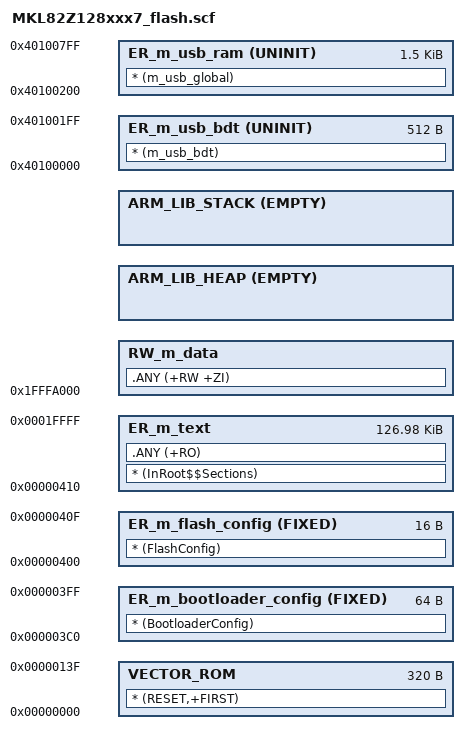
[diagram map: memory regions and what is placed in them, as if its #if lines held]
#! armcc -E
/*
** ###################################################################
**     Processors:          MKL82Z128VLH7
**                          MKL82Z128VLK7
**                          MKL82Z128VLL7
**                          MKL82Z128VMC7
**                          MKL82Z128VMP7
**
**     Compiler:            Keil ARM C/C++ Compiler
**     Reference manual:    KL82P121M72SF0RM, Rev.2 November 2015
**     Version:             rev. 1.5, 2015-09-24
**     Build:               b180801
**
**     Abstract:
**         Linker file for the Keil ARM C/C++ Compiler
**
**     Copyright 2016 Freescale Semiconductor, Inc.
**     Copyright 2016-2018 NXP
**
**     SPDX-License-Identifier: BSD-3-Clause
**
**     http:                 www.nxp.com
**     mail:                 support@nxp.com
**
** ###################################################################
*/

#define m_interrupts_start             0x00000000
#define m_interrupts_size              0x00000140

#define m_bootloader_config_start      0x000003C0
#define m_bootloader_config_size       0x00000040

#define m_flash_config_start           0x00000400
#define m_flash_config_size            0x00000010

#define m_text_start                   0x00000410
#define m_text_size                    0x0001FBF0

#define m_data_start                   0x1FFFA000
#define m_data_size                    0x00018000

#define m_usb_sram_start               0x40100000
#define m_usb_sram_size                0x00000800

/* USB BDT size */
#define usb_bdt_size                   0x200
/* Sizes */
#if (defined(__stack_size__))
  #define Stack_Size                   __stack_size__
#else
  #define Stack_Size                   0x2000
#endif

#if (defined(__heap_size__))
  #define Heap_Size                    __heap_size__
#else
  #define Heap_Size                    0x8000
#endif

LR_m_text m_interrupts_start m_text_start+m_text_size-m_interrupts_start { ; load region size_region
  VECTOR_ROM m_interrupts_start m_interrupts_size { ; load address = execution address
    * (RESET,+FIRST)
  }
  ER_m_bootloader_config m_bootloader_config_start FIXED m_bootloader_config_size { ; load address = execution address
    * (BootloaderConfig)
  }
  ER_m_flash_config m_flash_config_start FIXED m_flash_config_size { ; load address = execution address
    * (FlashConfig)
  }
  ER_m_text m_text_start m_text_size { ; load address = execution address
    * (InRoot$$Sections)
    .ANY (+RO)
  }

  RW_m_data m_data_start m_data_size-Stack_Size-Heap_Size { ; RW data
    .ANY (+RW +ZI)
  }
  ARM_LIB_HEAP +0 EMPTY Heap_Size {    ; Heap region growing up
  }
  ARM_LIB_STACK m_data_start+m_data_size EMPTY -Stack_Size { ; Stack region growing down
  }
}

LR_m_usb_bdt m_usb_sram_start usb_bdt_size {
  ER_m_usb_bdt m_usb_sram_start UNINIT usb_bdt_size {
    * (m_usb_bdt)
  }
}

LR_m_usb_ram (m_usb_sram_start + usb_bdt_size) (m_usb_sram_size - usb_bdt_size) {
  ER_m_usb_ram (m_usb_sram_start + usb_bdt_size) UNINIT (m_usb_sram_size - usb_bdt_size) {
    * (m_usb_global)
  }
}

